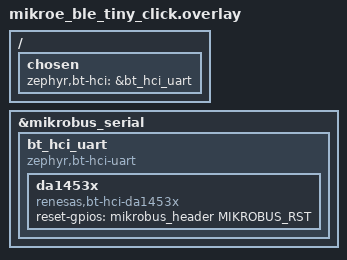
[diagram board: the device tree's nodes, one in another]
/*
 * Copyright (c) 2024 Ian Morris
 *
 * SPDX-License-Identifier: Apache-2.0
 */

#include <zephyr/dt-bindings/gpio/mikro-bus.h>

/ {
	chosen {
		zephyr,bt-hci = &bt_hci_uart;
	};
};

&mikrobus_serial {
	status = "okay";

	bt_hci_uart: bt_hci_uart {
		compatible = "zephyr,bt-hci-uart";
		status = "okay";

		da1453x {
			compatible = "renesas,bt-hci-da1453x";
			reset-gpios = <&mikrobus_header MIKROBUS_RST GPIO_ACTIVE_HIGH>;
			status = "okay";
		};
	};
};
